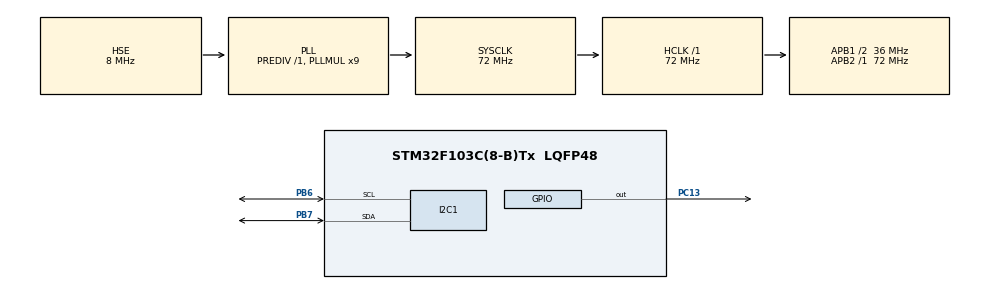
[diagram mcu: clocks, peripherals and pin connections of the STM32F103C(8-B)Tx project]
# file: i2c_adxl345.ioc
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I2C1.I2C_Mode=I2C_Fast
Mcu.Family=STM32F1
Mcu.Name=STM32F103C(8-B)Tx
Mcu.Package=LQFP48
NVIC.PriorityGroup=NVIC_PRIORITYGROUP_4
PA13.Mode=Serial_Wire
PA13.Signal=SYS_JTMS-SWDIO
PA14.Mode=Serial_Wire
PA14.Signal=SYS_JTCK-SWCLK
PB6.Mode=I2C
PB6.Signal=I2C1_SCL
PB7.Mode=I2C
PB7.Signal=I2C1_SDA
PC13-TAMPER-RTC.Signal=GPIO_Output
PD0-OSC_IN.Mode=HSE-External-Oscillator
PD0-OSC_IN.Signal=RCC_OSC_IN
PD1-OSC_OUT.Mode=HSE-External-Oscillator
PD1-OSC_OUT.Signal=RCC_OSC_OUT
ProjectManager.HeapSize=0x200
ProjectManager.StackSize=0x400
ProjectManager.TargetToolchain=STM32CubeIDE
RCC.AHBFreq_Value=72000000
RCC.APB1CLKDivider=RCC_HCLK_DIV2
RCC.APB1Freq_Value=36000000
RCC.APB1TimFreq_Value=72000000
RCC.APB2Freq_Value=72000000
RCC.APB2TimFreq_Value=72000000
RCC.HCLKFreq_Value=72000000
RCC.PLLMUL=RCC_PLL_MUL9
RCC.PLLSourceVirtual=RCC_PLLSOURCE_HSE
RCC.SYSCLKFreq_VALUE=72000000
RCC.SYSCLKSource=RCC_SYSCLKSOURCE_PLLCLK
RCC.USBFreq_Value=72000000
board=custom

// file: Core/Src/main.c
/* USER CODE BEGIN Header */
/**
  ******************************************************************************
  * @file           : main.c
  * @brief          : Main program body
  ******************************************************************************
  * @attention
  *
  * <h2><center>&copy; Copyright (c) 2020 STMicroelectronics.
  * All rights reserved.</center></h2>
  *
  * This software component is licensed by ST under BSD 3-Clause license,
  * the "License"; You may not use this file except in compliance with the
  * License. You may obtain a copy of the License at:
  *                        opensource.org/licenses/BSD-3-Clause
  *
  ******************************************************************************
  */
/* USER CODE END Header */

#include "main.h"

/* USER CODE BEGIN Includes */
#include "i2c-lcd.h"
#include "stdio.h"
/* USER CODE END Includes */

/* USER CODE BEGIN PTD */
#define adxl_address 0x53<<1
/* USER CODE END PTD */

I2C_HandleTypeDef hi2c1;

/* USER CODE BEGIN PV */

uint8_t data_rec[6];
uint8_t chipid=0;
int16_t x, y, z;
float xg, yg, zg;

/* USER CODE END PV */

void SystemClock_Config(void);
static void MX_GPIO_Init(void);
static void MX_I2C1_Init(void);

/* USER CODE BEGIN 0 */

/*-------write data-------*/

void adxl_write(uint8_t reg, uint8_t value)
{
	  uint8_t data[2];
	  data[0] = reg;
	  data[1] = value;
	  HAL_I2C_Master_Transmit(&hi2c1, adxl_address, data, 2, 10);
}

/*-------read data-------*/

void adxl_read_values(uint8_t reg)
{
	  HAL_I2C_Mem_Read(&hi2c1, adxl_address, reg, 1, (uint8_t *)data_rec, 6, 100);

}

void adxl_read_address (uint8_t reg)
{
	HAL_I2C_Mem_Read (&hi2c1, adxl_address, reg, 1, &chipid, 1, 100);
}

void adxl_init(void)
{
adxl_read_address(0x00);
adxl_write(0x31, 0x01);
adxl_write(0x2d, 0);
adxl_write(0x2d, 0x08);

}
/* USER CODE END 0 */

int main(void)
{

  /* MCU Configuration--------------------------------------------------------*/

  /* Reset of all peripherals, Initializes the Flash interface and the Systick. */
  HAL_Init();

  /* Configure the system clock */
  SystemClock_Config();

  /* Initialize all configured peripherals */
  MX_GPIO_Init();
  MX_I2C1_Init();
  /* USER CODE BEGIN 2 */

  //--------scanning address i2c----------
/*for (i = 0; i < 255; i++)
{
	if (HAL_I2C_IsDeviceReady(&hi2c1, i, 1, 10)== HAL_OK)
	{
	HAL_GPIO_TogglePin(GPIOC, GPIO_PIN_13);
	break;
	}
}*/

  adxl_init();

  lcd_init ();

  lcd_send_cmd (0x80|0x00);
  lcd_send_string ("Accelerometer");

  lcd_send_cmd (0x80|0x40);
  lcd_send_string ("Xg =");

  lcd_send_cmd (0x80|0x44);
  lcd_send_string ("xx");

  lcd_send_cmd (0x80|0x14);
  lcd_send_string ("Yg =");

  lcd_send_cmd (0x80|0x18);
  lcd_send_string ("xx");

  lcd_send_cmd (0x80|0x54);
  lcd_send_string ("Zg =");

  lcd_send_cmd (0x80|0x58);
  lcd_send_string ("xx");

  HAL_Delay(500);

  /* USER CODE END 2 */

  /* Infinite loop */
  while (1)
  {

    /* USER CODE BEGIN 3 */

	  /*-----------convert float to char-----------*/

	  /*-----------adxl read-----------*/

	  adxl_read_values(0x32);
	  x = ((data_rec[1]<<8) | data_rec[0]);
	  y = ((data_rec[3]<<8) | data_rec[2]);
	  z = ((data_rec[5]<<8) | data_rec[4]);
	  HAL_Delay(10);

	  /*-----------convert g-----------*/

	  xg = x * .0078;
	  yg = y * .0078;
	  zg = z * .0078;

	  /*-----------Display-----------*/

	  lcd_send_cmd (0x80|0x44);
	  lcd_send_string ("        ");
	  lcd_send_cmd (0x80|0x44);
	  lcd_send_float (xg, 5);

	  lcd_send_cmd (0x80|0x18);
	  lcd_send_string ("        ");
	  lcd_send_cmd (0x80|0x18);
	  lcd_send_float (yg, 5);

	  lcd_send_cmd (0x80|0x58);
	  lcd_send_string ("        ");
	  lcd_send_cmd (0x80|0x58);
	  lcd_send_float (zg, 5);
	  HAL_Delay(200);

  }
  /* USER CODE END 3 */
}

void SystemClock_Config(void)
{
  RCC_OscInitTypeDef RCC_OscInitStruct = {0};
  RCC_ClkInitTypeDef RCC_ClkInitStruct = {0};

  /** Initializes the CPU, AHB and APB busses clocks
  */
  RCC_OscInitStruct.OscillatorType = RCC_OSCILLATORTYPE_HSE;
  RCC_OscInitStruct.HSEState = RCC_HSE_ON;
  RCC_OscInitStruct.HSEPredivValue = RCC_HSE_PREDIV_DIV1;
  RCC_OscInitStruct.HSIState = RCC_HSI_ON;
  RCC_OscInitStruct.PLL.PLLState = RCC_PLL_ON;
  RCC_OscInitStruct.PLL.PLLSource = RCC_PLLSOURCE_HSE;
  RCC_OscInitStruct.PLL.PLLMUL = RCC_PLL_MUL9;
  if (HAL_RCC_OscConfig(&RCC_OscInitStruct) != HAL_OK)
  {
    Error_Handler();
  }
  /** Initializes the CPU, AHB and APB busses clocks
  */
  RCC_ClkInitStruct.ClockType = RCC_CLOCKTYPE_HCLK|RCC_CLOCKTYPE_SYSCLK
                              |RCC_CLOCKTYPE_PCLK1|RCC_CLOCKTYPE_PCLK2;
  RCC_ClkInitStruct.SYSCLKSource = RCC_SYSCLKSOURCE_PLLCLK;
  RCC_ClkInitStruct.AHBCLKDivider = RCC_SYSCLK_DIV1;
  RCC_ClkInitStruct.APB1CLKDivider = RCC_HCLK_DIV2;
  RCC_ClkInitStruct.APB2CLKDivider = RCC_HCLK_DIV1;

  if (HAL_RCC_ClockConfig(&RCC_ClkInitStruct, FLASH_LATENCY_2) != HAL_OK)
  {
    Error_Handler();
  }
}

static void MX_I2C1_Init(void)
{

  hi2c1.Instance = I2C1;
  hi2c1.Init.ClockSpeed = 400000;
  hi2c1.Init.DutyCycle = I2C_DUTYCYCLE_2;
  hi2c1.Init.OwnAddress1 = 0;
  hi2c1.Init.AddressingMode = I2C_ADDRESSINGMODE_7BIT;
  hi2c1.Init.DualAddressMode = I2C_DUALADDRESS_DISABLE;
  hi2c1.Init.OwnAddress2 = 0;
  hi2c1.Init.GeneralCallMode = I2C_GENERALCALL_DISABLE;
  hi2c1.Init.NoStretchMode = I2C_NOSTRETCH_DISABLE;
  if (HAL_I2C_Init(&hi2c1) != HAL_OK)
  {
    Error_Handler();
  }

}

static void MX_GPIO_Init(void)
{
  GPIO_InitTypeDef GPIO_InitStruct = {0};

  /* GPIO Ports Clock Enable */
  __HAL_RCC_GPIOC_CLK_ENABLE();
  __HAL_RCC_GPIOD_CLK_ENABLE();
  __HAL_RCC_GPIOA_CLK_ENABLE();
  __HAL_RCC_GPIOB_CLK_ENABLE();

  /*Configure GPIO pin Output Level */
  HAL_GPIO_WritePin(GPIOC, GPIO_PIN_13, GPIO_PIN_RESET);

  /*Configure GPIO pin : PC13 */
  GPIO_InitStruct.Pin = GPIO_PIN_13;
  GPIO_InitStruct.Mode = GPIO_MODE_OUTPUT_PP;
  GPIO_InitStruct.Pull = GPIO_NOPULL;
  GPIO_InitStruct.Speed = GPIO_SPEED_FREQ_LOW;
  HAL_GPIO_Init(GPIOC, &GPIO_InitStruct);

}

void Error_Handler(void)
{
}

/************************ (C) COPYRIGHT STMicroelectronics *****END OF FILE****/
